# QN908XC register map
Vendor: nxp.com; File version: 1.0
CPU: CM4 r0p1, little endian, no MPU, no FPU, 0x3 interrupt priority bits, 0x0 interrupts
Registers are 32-bit, read-write, reset 0x0 unless marked. A register's access mark holds for its fields unless they carry their own. Offsets are from the block's base; [hi:lo] are bit positions.

## DAC
Base 0x40007400
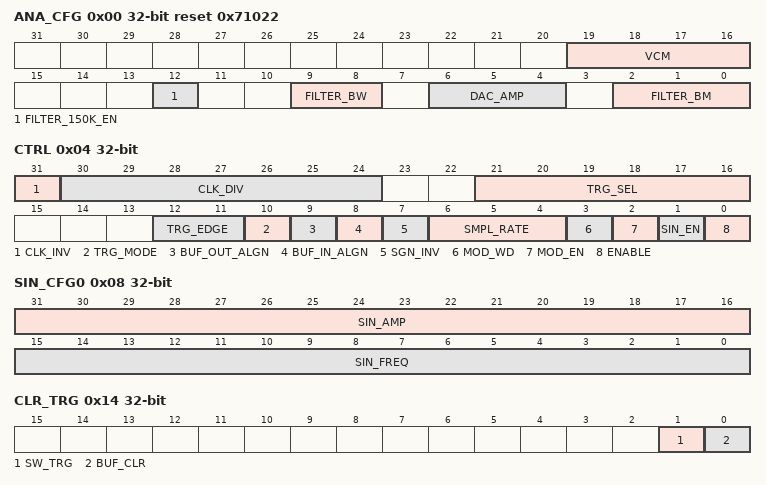
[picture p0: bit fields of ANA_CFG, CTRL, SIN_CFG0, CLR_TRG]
0x00 ANA_CFG reset 0x71022 — reserved
  [19:16] VCM — Set the common mode I of the driver.
  [12] FILTER_150K_EN — Set the filter type and bandwidth
  [9:8] FILTER_BW — Set the Miller compensation capacitance of the OPAMP. This compensation capacitance is determined by the off-chip load resistance
  [6:4] DAC_AMP — Set the current bias of the DAC
  [2:0] FILTER_BM — Set the filter bias current
0x04 CTRL — DAC clock invert
  [31] CLK_INV — DAC clock invert
  [30:24] CLK_DIV — DAC clock divider
  [21:16] TRG_SEL — Trigger select
  [12:11] TRG_EDGE — Trigger edge select
  [10] TRG_MODE — Trigger mode
  [9] BUF_OUT_ALGN — FIFO output data and Sine wave generator output align mode when no modulation mode
  [8] BUF_IN_ALGN — FIFO input data align
  [7] SGN_INV — Sign bit inverse
  [6:4] SMPL_RATE — sigma delta modulator down sample rate
  [3] MOD_WD — Modulator output width
  [2] MOD_EN — Modulator enable
  [1] SIN_EN — Sin wave enable
  [0] ENABLE — DAC module enable
0x08 SIN_CFG0 — sin amplitude
  [31:16] SIN_AMP — sin amplitude
  [15:0] SIN_FREQ — sin frequency
0x0C SIN_CFG1 — reserved
  [19:0] SIN_DC — DC value of sin wave
0x10 GAIN_CTRL reset 0x10 — reserved
  [7:0] GAIN_CTRL — digital FIFO output multiply with GAIN_CTRL to scale to certain range. Where GAIN_CTRL is a &lt;u 4 4&gt; value.
0x14 CLR_TRG reset not defined — Reserved
  [1] SW_TRG wo — Software trigger
  [0] BUF_CLR wo — clear buffer signal write 1 to clear.
0x18 DIN wo reset not defined — DAC data input
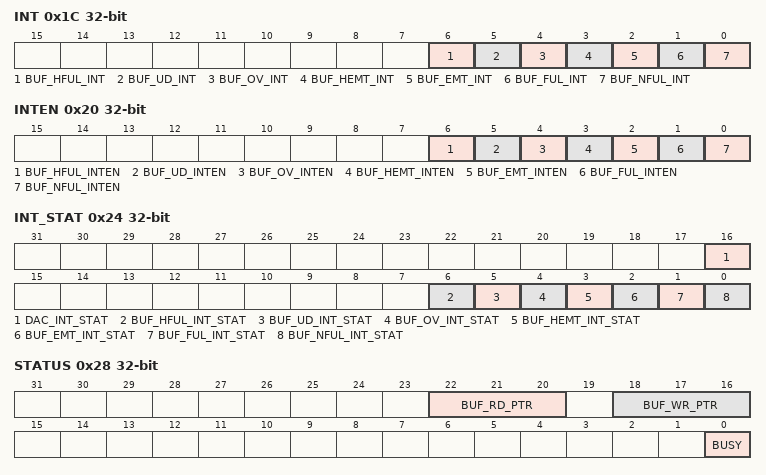
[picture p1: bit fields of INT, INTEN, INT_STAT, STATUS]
0x1C INT — Reserved
  [6] BUF_HFUL_INT ro — Buffer half full interrupt
  [5] BUF_UD_INT write-1-clears — Buffer underflow interrupt write 1 to clear
  [4] BUF_OV_INT write-1-clears — Buffer overflow interrupt write 1 to clear
  [3] BUF_HEMT_INT ro — buffer half empty interrupt
  [2] BUF_EMT_INT ro — Buffer empty interrupt
  [1] BUF_FUL_INT ro — Buffer full interrupt
  [0] BUF_NFUL_INT ro — Buffer not full interrupt
0x20 INTEN — Reserved
  [6] BUF_HFUL_INTEN — buffer half full interrupt enable
  [5] BUF_UD_INTEN — Buffer under flow interrupt enable
  [4] BUF_OV_INTEN — buffer over flow interrupt enable
  [3] BUF_HEMT_INTEN — buffer half empty interrupt enable
  [2] BUF_EMT_INTEN — buffer empty interrupt enable
  [1] BUF_FUL_INTEN — buffer full interrupt enable
  [0] BUF_NFUL_INTEN — buffer not full interrupt enable
0x24 INT_STAT ro — Reserved
  [16] DAC_INT_STAT — DAC all interrupt status
  [6] BUF_HFUL_INT_STAT — buffer half full interrupt status
  [5] BUF_UD_INT_STAT — Buffer under flow interrupt status
  [4] BUF_OV_INT_STAT — buffer over flow interrupt status
  [3] BUF_HEMT_INT_STAT — buffer half empty interrupt status
  [2] BUF_EMT_INT_STAT — buffer empty interrupt status
  [1] BUF_FUL_INT_STAT — buffer full interrupt status
  [0] BUF_NFUL_INT_STAT — buffer not full interrupt status
0x28 STATUS ro — Reserved
  [22:20] BUF_RD_PTR — Buffer read pointer
  [18:16] BUF_WR_PTR — Buffer write pointer
  [0] BUSY

## CS — tsc
Base 0x40007800
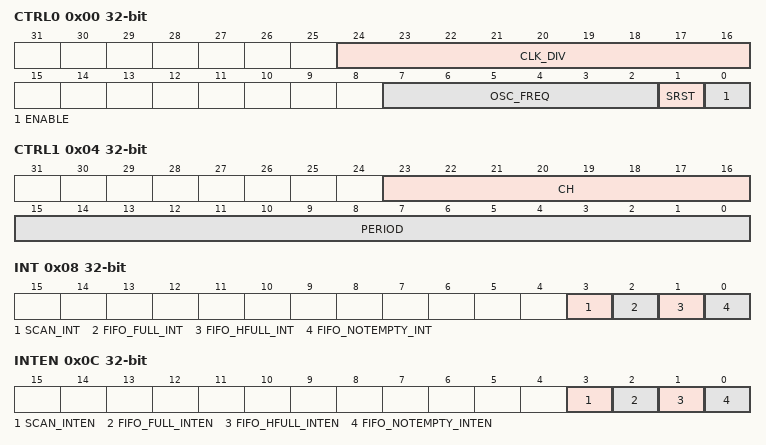
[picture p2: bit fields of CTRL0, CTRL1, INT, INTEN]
0x00 CTRL0 — CapSense control register 0
  [24:16] CLK_DIV — Clock divider from CLK_APB : CLK_CS_DIV = CLK_APB/(CLK_DIV + 1)
  [7:2] OSC_FREQ — Oscillation frequency control. The driving current will change accordingly.
  [1] SRST — Soft reset. Set 1 to reset, and 0 to de-assert.
  [0] ENABLE — CapSense enable. Write 1 to start work, 0 to stop.
    0=DISABLE (OSC work disable.); 1=ENABLE (OSC work enable.)
0x04 CTRL1 — CapSense control register 1
  [23:16] CH — Channel enable, each bit represent one channel, with CH[0] for CS0, CH[1] for CS1
  [15:0] PERIOD — The scan period for one channel, which is PERIOD/(CLK_DIV+1) clock cycles of CLK_APB.
0x08 INT — Interrupt status register
  [3] SCAN_INT write-1-clears — Scan done status flag for all enabled channels. Write 1 to clear.
  [2] FIFO_FULL_INT ro — FIFO full status indicator. Will clear automatically once not full.
  [1] FIFO_HFULL_INT ro — FIFO half full status indicator. Will clear automatically once less than half.
  [0] FIFO_NOTEMPTY_INT ro — FIFO not empty status indicator. Will clear automatically if no data available.
0x0C INTEN — Interrupt mask register
  [3] SCAN_INTEN — Interrupt mask of SCAN_INT. Set 1 to enable the interrupt.
  [2] FIFO_FULL_INTEN — Interrupt mask of FIFO_FULL_INT. Set 1 to enable the interrupt.
  [1] FIFO_HFULL_INTEN — Interrupt mask of FIFO_HFULL_INT. Set 1 to enable the interrupt.
  [0] FIFO_NOTEMPTY_INTEN — Interrupt mask of FIFO_NOTEMPTY_INT. Set 1 to enable the interrupt.
0x10 DATA ro — Output data register
  [18:0] DATA — Output data to MCU: DATA[18:16]: channel index, DATA[15:0]: counter output for that channel.
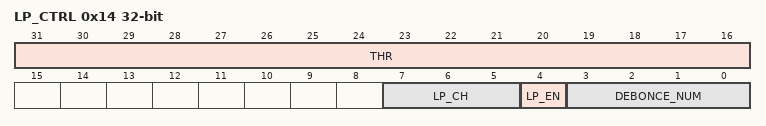
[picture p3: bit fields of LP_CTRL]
0x14 LP_CTRL — Control register for low power mode
  [31:16] THR — Threshold to decide the touch action.
  [7:5] LP_CH — The index of the channel to monitor in low power mode, representing 0~7.
  [4] LP_EN — Enable for low power mode.
    0=DISABLE (Low power mode disable.); 1=ENABLE (Low power mode enable.)
  [3:0] DEBONCE_NUM — (DEBONCE_NUM+1) consecutive samples to judge one touch action.
0x18 LP_INT ro — Low power interrupt register
  [0] LP_INT — Interrupt in low power mode when counter output is less than THR.
0x1C LP_INTEN — low power interrupt enable register
  [0] LP_INTEN — Interrupt enable of LP_INT. Set 1 to enable.
0x20 IDLE_PERIOD — Idle preiod number register
  [15:0] IDLE_PERIOD — Number of idle period. Zero represents no idle time between consecutive scan.
